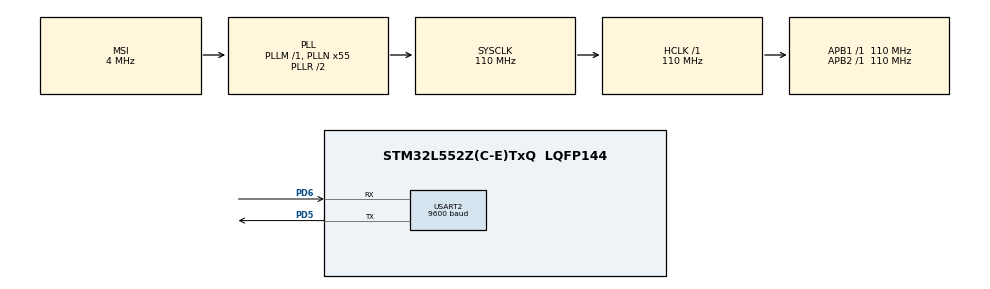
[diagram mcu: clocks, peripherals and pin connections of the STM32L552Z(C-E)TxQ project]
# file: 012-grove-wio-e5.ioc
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Dma.Request0=USART2_RX
Dma.Request1=USART2_TX
Dma.USART2_RX.0.Channel_PRIV_NPRIV=DMA_CHANNEL_NPRIV_DISABLE
Dma.USART2_RX.0.Direction=DMA_PERIPH_TO_MEMORY
Dma.USART2_RX.0.EventEnable=DISABLE
Dma.USART2_RX.0.Instance=DMA1_Channel1
Dma.USART2_RX.0.MemDataAlignment=DMA_MDATAALIGN_BYTE
Dma.USART2_RX.0.MemInc=DMA_MINC_ENABLE
Dma.USART2_RX.0.Mode=DMA_CIRCULAR
Dma.USART2_RX.0.PeriphDataAlignment=DMA_PDATAALIGN_BYTE
Dma.USART2_RX.0.PeriphInc=DMA_PINC_DISABLE
Dma.USART2_RX.0.Polarity=HAL_DMAMUX_REQ_GEN_RISING
Dma.USART2_RX.0.Priority=DMA_PRIORITY_LOW
Dma.USART2_RX.0.RequestNumber=1
Dma.USART2_RX.0.SignalID=NONE
Dma.USART2_RX.0.SyncEnable=DISABLE
Dma.USART2_RX.0.SyncPolarity=HAL_DMAMUX_SYNC_NO_EVENT
Dma.USART2_RX.0.SyncRequestNumber=1
Dma.USART2_RX.0.SyncSignalID=NONE
Dma.USART2_TX.1.Channel_PRIV_NPRIV=DMA_CHANNEL_NPRIV_DISABLE
Dma.USART2_TX.1.Direction=DMA_MEMORY_TO_PERIPH
Dma.USART2_TX.1.EventEnable=DISABLE
Dma.USART2_TX.1.Instance=DMA1_Channel2
Dma.USART2_TX.1.MemDataAlignment=DMA_MDATAALIGN_BYTE
Dma.USART2_TX.1.MemInc=DMA_MINC_ENABLE
Dma.USART2_TX.1.Mode=DMA_NORMAL
Dma.USART2_TX.1.PeriphDataAlignment=DMA_PDATAALIGN_BYTE
Dma.USART2_TX.1.PeriphInc=DMA_PINC_DISABLE
Dma.USART2_TX.1.Polarity=HAL_DMAMUX_REQ_GEN_RISING
Dma.USART2_TX.1.Priority=DMA_PRIORITY_LOW
Dma.USART2_TX.1.RequestNumber=1
Dma.USART2_TX.1.SignalID=NONE
Dma.USART2_TX.1.SyncEnable=DISABLE
Dma.USART2_TX.1.SyncPolarity=HAL_DMAMUX_SYNC_NO_EVENT
Dma.USART2_TX.1.SyncRequestNumber=1
Dma.USART2_TX.1.SyncSignalID=NONE
Mcu.Family=STM32L5
Mcu.Name=STM32L552Z(C-E)TxQ
Mcu.Package=LQFP144
Mcu.TrustZone=disable
NUCLEO-L552ZE-Q.BUTTON=1
NUCLEO-L552ZE-Q.LD1=true
NUCLEO-L552ZE-Q.LD2=true
NUCLEO-L552ZE-Q.LD3=true
NUCLEO-L552ZE-Q.VCP=true
NVIC.DMA1_Channel1_IRQn=true\:0\:0\:false\:false\:true\:false\:true\:true
NVIC.DMA1_Channel2_IRQn=true\:0\:0\:false\:false\:true\:false\:true\:true
NVIC.EXTI13_IRQn=true\:0\:0\:false\:false\:true\:false\:true\:true
NVIC.PriorityGroup=NVIC_PRIORITYGROUP_3
NVIC.USART2_IRQn=true\:0\:0\:false\:false\:true\:true\:true\:true
PA13\ (JTMS/SWDIO).Signal=DEBUG_JTMS-SWDIO
PA14\ (JTCK/SWCLK).Signal=DEBUG_JTCK-SWCLK
PB3\ (JTDO/TRACESWO).Signal=DEBUG_JTDO-SWO
PC14-OSC32_IN\ (PC14).Signal=RCC_OSC32_IN
PC15-OSC32_OUT\ (PC15).Signal=RCC_OSC32_OUT
PD5.Mode=Asynchronous
PD5.Signal=USART2_TX
PD6.Mode=Asynchronous
PD6.Signal=USART2_RX
PG7.Signal=LPUART1_TX
PG8.Signal=LPUART1_RX
ProjectManager.HeapSize=0x200
ProjectManager.StackSize=0x400
ProjectManager.TargetToolchain=STM32CubeIDE
RCC.ADCCLockSelection=RCC_ADCCLKSOURCE_SYSCLK
RCC.ADCFreq_Value=110000000
RCC.AHBFreq_Value=110000000
RCC.APB1Freq_Value=110000000
RCC.APB1TimFreq_Value=110000000
RCC.APB2Freq_Value=110000000
RCC.APB2TimFreq_Value=110000000
RCC.CK48CLockSelection=RCC_USBCLKSOURCE_HSI48
RCC.CortexFreq_Value=110000000
RCC.HCLKFreq_Value=110000000
RCC.HSE_VALUE=8000000
RCC.HSI48_VALUE=48000000
RCC.HSI_VALUE=16000000
RCC.LSE_VALUE=32768
RCC.MSI_VALUE=4000000
RCC.PLLN=55
RCC.PLLSAI1N=24
RCC.RTCClockSelection=RCC_RTCCLKSOURCE_LSE
RCC.SYSCLKFreq_VALUE=110000000
RCC.SYSCLKSource=RCC_SYSCLKSOURCE_PLLCLK
RCC.USBFreq_Value=48000000
RCC.VCOOutputFreq_Value=220000000
USART2.BaudRate=9600
USART2.VirtualMode-Asynchronous=VM_ASYNC
VP_ICACHE_VS_ICACHE.Mode=DirectMappedCache
VP_NUCLEO-L552ZE-Q_VS_BSP_COMMON.Mode=COMMON
VP_PWR_VS_DBSignals.Mode=DisableDeadBatterySignals
VP_PWR_VS_SECSignals.Mode=Security/Privilege
board=NUCLEO-L552ZE-Q

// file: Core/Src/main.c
/* USER CODE BEGIN Header */
/**
  ******************************************************************************
  * @file           : main.c
  * @brief          : Main program body
  ******************************************************************************
  * @attention
  *
  * Copyright (c) 2026 STMicroelectronics.
  * All rights reserved.
  *
  * This software is licensed under terms that can be found in the LICENSE file
  * in the root directory of this software component.
  * If no LICENSE file comes with this software, it is provided AS-IS.
  *
  ******************************************************************************
  */
/* USER CODE END Header */
#include "main.h"

/* USER CODE BEGIN Includes */
#include "lora-e5.h"
#include <string.h>
#include <stdio.h>
#include <stdlib.h>
/* USER CODE END Includes */

COM_InitTypeDef BspCOMInit;

UART_HandleTypeDef huart2;
DMA_HandleTypeDef hdma_usart2_rx;
DMA_HandleTypeDef hdma_usart2_tx;

/* USER CODE BEGIN PV */

/* LoRa-E5 Handle */
LoRa_Handle_t hLoRa;

/* LoRaWAN Configuration */
#define LORA_APP_EUI    "0000000000000000"
#define LORA_DEV_EUI    "0000000000000000"
#define LORA_APP_KEY    "00000000000000000000000000000000"
/* USER CODE END PV */

void SystemClock_Config(void);
static void MX_GPIO_Init(void);
static void MX_DMA_Init(void);
static void MX_ICACHE_Init(void);
static void MX_USART2_UART_Init(void);

int main(void)
{

  /* MCU Configuration--------------------------------------------------------*/

  /* Reset of all peripherals, Initializes the Flash interface and the Systick. */
  HAL_Init();

  /* Configure the system clock */
  SystemClock_Config();

  /* Initialize all configured peripherals */
  MX_GPIO_Init();
  MX_DMA_Init();
  MX_ICACHE_Init();
  MX_USART2_UART_Init();

  /* Initialize leds */
  BSP_LED_Init(LED_GREEN);
  BSP_LED_Init(LED_BLUE);
  BSP_LED_Init(LED_RED);

  /* Initialize USER push-button, will be used to trigger an interrupt each time it's pressed.*/
  BSP_PB_Init(BUTTON_USER, BUTTON_MODE_EXTI);

  /* Initialize COM1 port (115200, 8 bits (7-bit data + 1 stop bit), no parity */
  BspCOMInit.BaudRate   = 115200;
  BspCOMInit.WordLength = COM_WORDLENGTH_8B;
  BspCOMInit.StopBits   = COM_STOPBITS_1;
  BspCOMInit.Parity     = COM_PARITY_NONE;
  BspCOMInit.HwFlowCtl  = COM_HWCONTROL_NONE;
  if (BSP_COM_Init(COM1, &BspCOMInit) != BSP_ERROR_NONE)
  {
    Error_Handler();
  }

  /* Infinite loop */
  /* USER CODE BEGIN WHILE */
  /* USER CODE BEGIN LoRa_Init */
  printf("\r\n=== Grove Wio-E5 LoRa Module Test ===\r\n");
  printf("Initializing LoRa-E5 module...\r\n");

  /* Initialize LoRa-E5 module with USART2 */
  if (LoRa_Init(&hLoRa, &huart2) != LORA_OK) {
      printf("ERROR: Failed to initialize LoRa-E5 module!\r\n");
      BSP_LED_On(LED_RED);
  } else {
      printf("LoRa-E5 module initialized successfully!\r\n");
      BSP_LED_On(LED_GREEN);

      /* Get and display module version */
      char version_buf[128];
      LoRa_GetVersion(&hLoRa, version_buf, LORA_DEFAULT_TIMEOUT);
      printf("Version: %s\r\n", version_buf);

      /* Get Device EUI */
      char id_buf[128];
      LoRa_GetId(&hLoRa, id_buf, LORA_ID_DEV_EUI, LORA_DEFAULT_TIMEWAIT);
      printf("DevEUI: %s\r\n", id_buf);

      /* Configure for OTAA mode */
      printf("\r\nConfiguring for OTAA mode...\r\n");
      LoRa_SetDeviceMode(&hLoRa, LORA_MODE_LWOTAA);

      /* Set region */
      printf("Setting region to AS923...\r\n");
      LoRa_SetFrequencyBand(&hLoRa, LORA_REGION_AS923);

      /* Set keys */
      printf("Setting LoRaWAN keys...\r\n");
      LoRa_SetId(&hLoRa, NULL, LORA_DEV_EUI, LORA_APP_EUI);
      LoRa_SetKey(&hLoRa, NULL, NULL, LORA_APP_KEY);

      /* Set Class A */
      LoRa_SetClassType(&hLoRa, LORA_CLASS_A);

      /* Disable ADR for testing */
      LoRa_SetAdaptiveDataRate(&hLoRa, false);

      /* Set data rate */
      LoRa_SetDataRate(&hLoRa, LORA_DR5, LORA_REGION_UNINIT);

      printf("Configuration complete!\r\n");
      printf("\r\nAttempting to join network (this may take a while)...\r\n");

      /* join the network */
      if (LoRa_JoinOTAA(&hLoRa, LORA_JOIN_JOIN, 30000) > 0) {
          printf("Successfully joined the network!\r\n");
          BSP_LED_Off(LED_GREEN);
          BSP_LED_On(LED_BLUE);
      } else {
          printf("Failed to join network. Check your keys and gateway.\r\n");
          BSP_LED_On(LED_RED);
      }
  }
  /* USER CODE END LoRa_Init */

  uint32_t last_tx_time = 0;
  uint32_t tx_counter = 0;
  char tx_buffer[64];

  while (1)
  {
    /* Send a test message every 30 seconds */
    if (HAL_GetTick() - last_tx_time >= 30000) {
        last_tx_time = HAL_GetTick();
        tx_counter++;

        /* Create test payload */
        snprintf(tx_buffer, sizeof(tx_buffer), "Hello LoRa #%lu", tx_counter);

        printf("\r\nSending: %s\r\n", tx_buffer);
        BSP_LED_Toggle(LED_GREEN);

        /* Send unconfirmed message */
        if (LoRa_TransferPacket(&hLoRa, tx_buffer, LORA_DEFAULT_TIMEOUT) > 0) {
            printf("Message sent successfully!\r\n");
        } else {
            printf("Failed to send message.\r\n");
        }
    }

    HAL_Delay(500);
    /* USER CODE END WHILE */

  }
}

void SystemClock_Config(void)
{
  RCC_OscInitTypeDef RCC_OscInitStruct = {0};
  RCC_ClkInitTypeDef RCC_ClkInitStruct = {0};

  /** Configure the main internal regulator output voltage
  */
  if (HAL_PWREx_ControlVoltageScaling(PWR_REGULATOR_VOLTAGE_SCALE0) != HAL_OK)
  {
    Error_Handler();
  }

  /** Initializes the RCC Oscillators according to the specified parameters
  * in the RCC_OscInitTypeDef structure.
  */
  RCC_OscInitStruct.OscillatorType = RCC_OSCILLATORTYPE_MSI;
  RCC_OscInitStruct.MSIState = RCC_MSI_ON;
  RCC_OscInitStruct.MSICalibrationValue = RCC_MSICALIBRATION_DEFAULT;
  RCC_OscInitStruct.MSIClockRange = RCC_MSIRANGE_6;
  RCC_OscInitStruct.PLL.PLLState = RCC_PLL_ON;
  RCC_OscInitStruct.PLL.PLLSource = RCC_PLLSOURCE_MSI;
  RCC_OscInitStruct.PLL.PLLM = 1;
  RCC_OscInitStruct.PLL.PLLN = 55;
  RCC_OscInitStruct.PLL.PLLP = RCC_PLLP_DIV7;
  RCC_OscInitStruct.PLL.PLLQ = RCC_PLLQ_DIV2;
  RCC_OscInitStruct.PLL.PLLR = RCC_PLLR_DIV2;
  if (HAL_RCC_OscConfig(&RCC_OscInitStruct) != HAL_OK)
  {
    Error_Handler();
  }

  /** Initializes the CPU, AHB and APB buses clocks
  */
  RCC_ClkInitStruct.ClockType = RCC_CLOCKTYPE_HCLK|RCC_CLOCKTYPE_SYSCLK
                              |RCC_CLOCKTYPE_PCLK1|RCC_CLOCKTYPE_PCLK2;
  RCC_ClkInitStruct.SYSCLKSource = RCC_SYSCLKSOURCE_PLLCLK;
  RCC_ClkInitStruct.AHBCLKDivider = RCC_SYSCLK_DIV1;
  RCC_ClkInitStruct.APB1CLKDivider = RCC_HCLK_DIV1;
  RCC_ClkInitStruct.APB2CLKDivider = RCC_HCLK_DIV1;

  if (HAL_RCC_ClockConfig(&RCC_ClkInitStruct, FLASH_LATENCY_5) != HAL_OK)
  {
    Error_Handler();
  }
}

static void MX_ICACHE_Init(void)
{

  /** Enable instruction cache in 1-way (direct mapped cache)
  */
  if (HAL_ICACHE_ConfigAssociativityMode(ICACHE_1WAY) != HAL_OK)
  {
    Error_Handler();
  }
  if (HAL_ICACHE_Enable() != HAL_OK)
  {
    Error_Handler();
  }

}

static void MX_USART2_UART_Init(void)
{

  huart2.Instance = USART2;
  huart2.Init.BaudRate = 9600;
  huart2.Init.WordLength = UART_WORDLENGTH_8B;
  huart2.Init.StopBits = UART_STOPBITS_1;
  huart2.Init.Parity = UART_PARITY_NONE;
  huart2.Init.Mode = UART_MODE_TX_RX;
  huart2.Init.HwFlowCtl = UART_HWCONTROL_NONE;
  huart2.Init.OverSampling = UART_OVERSAMPLING_16;
  huart2.Init.OneBitSampling = UART_ONE_BIT_SAMPLE_DISABLE;
  huart2.Init.ClockPrescaler = UART_PRESCALER_DIV1;
  huart2.AdvancedInit.AdvFeatureInit = UART_ADVFEATURE_NO_INIT;
  if (HAL_UART_Init(&huart2) != HAL_OK)
  {
    Error_Handler();
  }
  if (HAL_UARTEx_SetTxFifoThreshold(&huart2, UART_TXFIFO_THRESHOLD_1_8) != HAL_OK)
  {
    Error_Handler();
  }
  if (HAL_UARTEx_SetRxFifoThreshold(&huart2, UART_RXFIFO_THRESHOLD_1_8) != HAL_OK)
  {
    Error_Handler();
  }
  if (HAL_UARTEx_DisableFifoMode(&huart2) != HAL_OK)
  {
    Error_Handler();
  }

}

static void MX_DMA_Init(void)
{

  /* DMA controller clock enable */
  __HAL_RCC_DMAMUX1_CLK_ENABLE();
  __HAL_RCC_DMA1_CLK_ENABLE();

  /* DMA interrupt init */
  /* DMA1_Channel1_IRQn interrupt configuration */
  HAL_NVIC_SetPriority(DMA1_Channel1_IRQn, 0, 0);
  HAL_NVIC_EnableIRQ(DMA1_Channel1_IRQn);
  /* DMA1_Channel2_IRQn interrupt configuration */
  HAL_NVIC_SetPriority(DMA1_Channel2_IRQn, 0, 0);
  HAL_NVIC_EnableIRQ(DMA1_Channel2_IRQn);

}

static void MX_GPIO_Init(void)
{

  /* GPIO Ports Clock Enable */
  __HAL_RCC_GPIOC_CLK_ENABLE();
  __HAL_RCC_GPIOA_CLK_ENABLE();
  __HAL_RCC_GPIOD_CLK_ENABLE();
  __HAL_RCC_GPIOB_CLK_ENABLE();

}

/* USER CODE BEGIN 4 */
void HAL_UART_RxCpltCallback(UART_HandleTypeDef *UartHandle)
{

  (void)UartHandle;
}

void HAL_UART_ErrorCallback(UART_HandleTypeDef *huart)
{
  if (huart->Instance == USART2) {
      LoRa_UART_ErrorCallback(&hLoRa);
  }
}

void HAL_UART_TxCpltCallback(UART_HandleTypeDef *huart)
{
  /* Handle LoRa-E5 DMA TX complete */
  if (huart->Instance == USART2) {
      LoRa_DMA_TxCpltCallback(&hLoRa);
      return;
  }

}
/* USER CODE END 4 */

void Error_Handler(void)
{
  __disable_irq();
  while (1)
  {
  }
}
